AUTOSAR XML (schema 4-3-0)
package /CAN1/ISignalGroup
  26 x i signal group:
    CAN1_SG_ASC2_A: i-signal=[CAN1_AutoTracH, CAN1_DamStiffReqFA, CAN1_DamStiffReqLA, CAN1_DamStiffReqRA, CAN1_KneeCtrlMReq, CAN1_KneeReqFA, CAN1_KneeReqLSide, CAN1_KneeReqRA, CAN1_KneeReqRSide, CAN1_LA1PosCmd, CAN1_LA2PosCmd, CAN1_LvCtrlModeReq, CAN1_NLvReqFA, CAN1_NLvReqRA], system-signal-group=CAN1_SG_ASC2_A
    CAN1_SG_CCVS: i-signal=[CAN1_BrakeSW, CAN1_ParkBrakeSW, CAN1_VCUVehSpd], system-signal-group=CAN1_SG_CCVS
    CAN1_SG_CFGEM1_BAM: i-signal=[CAN1_CFGEM1BAMPGN, CAN1_CFGEM1BAMRsv, CAN1_CFGEM1BAMTNum, CAN1_CFGEM1BAMTSize, CAN1_CFGEM1Ctrl], system-signal-group=CAN1_SG_CFGEM1_BAM
    CAN1_SG_CFGEM1_DT: i-signal=[CAN1_CFGEM1DT0, CAN1_CFGEM1DT1, CAN1_CFGEM1DT2, CAN1_CFGEM1DT3, CAN1_CFGEM1DT4, CAN1_CFGEM1DT5, CAN1_CFGEM1DT6, CAN1_CFGEM1DT7], system-signal-group=CAN1_SG_CFGEM1_DT
    CAN1_SG_DCDC_Status_1: i-signal=[CAN1_DCDCEnSta, CAN1_DCDCErrCode, CAN1_DCDCErrLv, CAN1_DCDCInCurr, CAN1_DCDCInVol, CAN1_DCDCLifeSig, CAN1_DCDCTempe], system-signal-group=CAN1_SG_DCDC_Status_1
    CAN1_SG_DCDC_Status_2: i-signal=[CAN1_DCDCOutCurr, CAN1_DCDCOutVol, CAN1_DCDCSWVer], system-signal-group=CAN1_SG_DCDC_Status_2
    CAN1_SG_EAC_Status_1: i-signal=[CAN1_EACEnSta, CAN1_EACErrCode, CAN1_EACErrLv, CAN1_EACHVILSig, CAN1_EACInVol, CAN1_EACInvTempe, CAN1_EACLifeSig, CAN1_EACMotorTempe], system-signal-group=CAN1_SG_EAC_Status_1
    CAN1_SG_EBC1: i-signal=[CAN1_ABSFullyOper, CAN1_ABSOffroadSw, CAN1_ASRBrakeCtrlAtc, CAN1_ASREngCtrlAtc, CAN1_ASRHillHolderSw, CAN1_ASROffroadSw, CAN1_ATCASRInfoSig, CAN1_AcltrInterlockSw, CAN1_AntiLBrakABSAct, CAN1_BrakePedalPos, CAN1_EBSAmWarnLampSta, CAN1_EBSBrakeSw, CAN1_EBSRedWarnLampSta, CAN1_EngAuxShutdownSw, CAN1_EngDerateSw, CAN1_EngRetSel, CAN1_HaltBrakeSw, CAN1_RmAccelEnSw, CAN1_SACtrlBrakeCtrl, CAN1_TractCtrlOvrSw, CAN1_TrailerABSSta, CAN1_TrailerABSWarnSig], system-signal-group=CAN1_SG_EBC1
    CAN1_SG_EBC2: i-signal=[CAN1_FASpeed, CAN1_RelaSpdFALWheel, CAN1_RelaSpdFARWheel, CAN1_RelaSpdRA1LWheel, CAN1_RelaSpdRA1RWheel, CAN1_RelaSpdRA2LWheel, CAN1_RelaSpdRA2RWheel], system-signal-group=CAN1_SG_EBC2
    CAN1_SG_EBC5: i-signal=[CAN1_BrkTempeWarn, CAN1_FndBrkUse, CAN1_HaltBrkMode, CAN1_HillHolderMode, CAN1_ParkBrkActuFAct, CAN1_XBRAcltnLimit, CAN1_XBRActtrlMode, CAN1_XBRSysSta], system-signal-group=CAN1_SG_EBC5
    CAN1_SG_EEC2: i-signal=[CAN1_AccPedal1LowSW, CAN1_AccPedalPos1, CAN1_EEC2MSGCS, CAN1_EEC2MSGCnt], system-signal-group=CAN1_SG_EEC2
    CAN1_SG_EEC3: i-signal=[CAN1_EMParasLoss, CAN1_NFricPercTorq], system-signal-group=CAN1_SG_EEC3
    CAN1_SG_EHPS_Status_1: i-signal=[CAN1_EHPSEnSta, CAN1_EHPSErrCode, CAN1_EHPSErrLv, CAN1_EHPSHVILSig, CAN1_EHPSInVol, CAN1_EHPSInvTemp, CAN1_EHPSLifeSig, CAN1_EHPSMotorTempe], system-signal-group=CAN1_SG_EHPS_Status_1
    CAN1_SG_EMC1_EM1: i-signal=[CAN1_EM1CS, CAN1_EM1Cnt, CAN1_EM1OvrCtrlMBrk, CAN1_EM1OvrCtrlMDriv, CAN1_EM1OvrCtrlMPriBrk, CAN1_EM1OvrCtrlMPriDriv, CAN1_EM1ReqTorqHRlsBrk, CAN1_EM1ReqTorqHRlsDri, CAN1_EM1ReqTorqLimBrk, CAN1_EM1ReqTorqLimDriv], system-signal-group=CAN1_SG_EMC1_EM1
    CAN1_SG_EMRC1: i-signal=[CAN1_ActEMOutSftSpd, CAN1_ActEMpTrq, CAN1_ActEMpTrqHrls, CAN1_ActMaxAvaEMRecpTrq, CAN1_DrvDemEMRtapTrq, CAN1_EMTrqModeDrvBrk, CAN1_RetSelNonEng, CAN1_SACtrlDev], system-signal-group=CAN1_SG_EMRC1
    CAN1_SG_EPB1: i-signal=CAN1_EPB_ParkingBrake_Sta, system-signal-group=CAN1_SG_EPB1
    CAN1_SG_ETC1: i-signal=[CAN1_DLEngaged, CAN1_ShiftPgs], system-signal-group=CAN1_SG_ETC1
    CAN1_SG_ETC2: i-signal=CAN1_ActDriveDirect, system-signal-group=CAN1_SG_ETC2
    CAN1_SG_FD1_C100_1: i-signal=[CAN1_FDC_CHA_EBSHBSw_Sta, CAN1_FDC_CHA_EBSHHSw_Sta], system-signal-group=CAN1_SG_FD1_C100_1
    CAN1_SG_FD1_C100_2: i-signal=CAN1_FDC_CHA_EBSRd4BR_Sta, system-signal-group=CAN1_SG_FD1_C100_2
    CAN1_SG_FD1_C100_3: i-signal=[CAN1_DCDCEnDemand, CAN1_EACSpdDemand, CAN1_EHPSEnDemand, CAN1_EHPSSpdDemand, CAN1_FDC_CHA_EACEnDemand_Cmd], system-signal-group=CAN1_SG_FD1_C100_3
    CAN1_SG_FD1_CE100_1: i-signal=CAN1_FDC_BCM_DoorSta_Sta, system-signal-group=CAN1_SG_FD1_CE100_1
    CAN1_SG_GW1_C1000_1: i-signal=CAN1_SeatBeltSwitch, system-signal-group=CAN1_SG_GW1_C1000_1
    CAN1_SG_GW1_C100_4: i-signal=[CAN1_OpenStatusOfDoor1, CAN1_OpenStatusOfDoor2], system-signal-group=CAN1_SG_GW1_C100_4
    CAN1_SG_PDU_Status_1: i-signal=[CAN1_HVILSta_T1_PDU, CAN1_PDUACLoopSta, CAN1_PDUACPreRlySta, CAN1_PDUACRlySta, CAN1_PDUDCDCRlySta, CAN1_PDUEACRlySta, CAN1_PDUEHPSRlySta, CAN1_PDULifeSig, CAN1_PDUMCUHVLoopSta, CAN1_PDUMCUPosRlySta, CAN1_PDUMCUPreRlySta, CAN1_PDUSWVer, CAN1_PDUSelfChkSta], system-signal-group=CAN1_SG_PDU_Status_1
    CAN1_SG_VCU_PDU_Demand_1: i-signal=[CAN1_DCDCRlyEn, CAN1_EACRlyEn, CAN1_EHPSRlyEn, CAN1_VCULife1], system-signal-group=CAN1_SG_VCU_PDU_Demand_1
package /CAN1/Cluster
  can cluster CAN1: baudrate=500
    can physical channel CAN1: comm-connectors=ConnCAN1
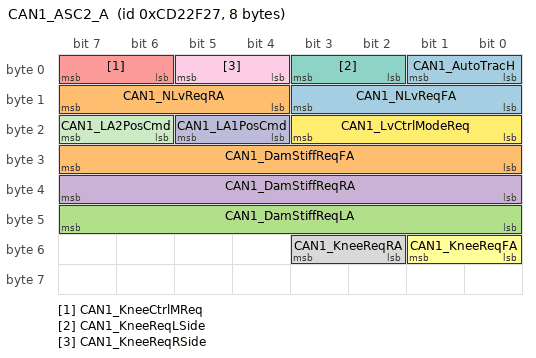
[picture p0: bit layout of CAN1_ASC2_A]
      frame CAN1_ASC2_A: id 0xCD22F27, frame-length=8, can-addressing-mode=EXTENDED, can-fd-frame-support=false, can-frame-rx-behavior=CAN-20, can-frame-tx-behavior=CAN-20
        pdu CAN1_ASC2_A: length=8, minimum-delay=0.0, transmission-mode-true-timing=cyclic-timing=time-period=0.1, unused-bit-pattern=0
          mapping CAN1_SG_ASC2_A: i-signal-group=CAN1_SG_ASC2_A, start-position=0, transfer-property=PENDING
          signal CAN1_AutoTracH: start 0, 2 bit, little-endian, i-signal-type=PRIMITIVE, init-value=constant-reference=Init_CAN1_AutoTracH, base-type=uint8, implementation-data-type=uint8, transfer-property=PENDING
          signal CAN1_DamStiffReqFA: start 24, 8 bit, little-endian, i-signal-type=PRIMITIVE, init-value=constant-reference=Init_CAN1_DamStiffReqFA, base-type=uint8, implementation-data-type=uint8, transfer-property=PENDING
          signal CAN1_DamStiffReqLA: start 40, 8 bit, little-endian, i-signal-type=PRIMITIVE, init-value=constant-reference=Init_CAN1_DamStiffReqLA, base-type=uint8, implementation-data-type=uint8, transfer-property=PENDING
          signal CAN1_DamStiffReqRA: start 32, 8 bit, little-endian, i-signal-type=PRIMITIVE, init-value=constant-reference=Init_CAN1_DamStiffReqRA, base-type=uint8, implementation-data-type=uint8, transfer-property=PENDING
          signal CAN1_KneeCtrlMReq: start 6, 2 bit, little-endian, i-signal-type=PRIMITIVE, init-value=constant-reference=Init_CAN1_KneeCtrlMReq, base-type=uint8, implementation-data-type=uint8, transfer-property=PENDING
          signal CAN1_KneeReqFA: start 48, 2 bit, little-endian, i-signal-type=PRIMITIVE, init-value=constant-reference=Init_CAN1_KneeReqFA, base-type=uint8, implementation-data-type=uint8, transfer-property=PENDING
          signal CAN1_KneeReqLSide: start 2, 2 bit, little-endian, i-signal-type=PRIMITIVE, init-value=constant-reference=Init_CAN1_KneeReqLSide, base-type=uint8, implementation-data-type=uint8, transfer-property=PENDING
          signal CAN1_KneeReqRA: start 50, 2 bit, little-endian, i-signal-type=PRIMITIVE, init-value=constant-reference=Init_CAN1_KneeReqRA, base-type=uint8, implementation-data-type=uint8, transfer-property=PENDING
          signal CAN1_KneeReqRSide: start 4, 2 bit, little-endian, i-signal-type=PRIMITIVE, init-value=constant-reference=Init_CAN1_KneeReqRSide, base-type=uint8, implementation-data-type=uint8, transfer-property=PENDING
          signal CAN1_LA1PosCmd: start 20, 2 bit, little-endian, i-signal-type=PRIMITIVE, init-value=constant-reference=Init_CAN1_LA1PosCmd, base-type=uint8, implementation-data-type=uint8, transfer-property=PENDING
          signal CAN1_LA2PosCmd: start 22, 2 bit, little-endian, i-signal-type=PRIMITIVE, init-value=constant-reference=Init_CAN1_LA2PosCmd, base-type=uint8, implementation-data-type=uint8, transfer-property=PENDING
          signal CAN1_LvCtrlModeReq: start 16, 4 bit, little-endian, i-signal-type=PRIMITIVE, init-value=constant-reference=Init_CAN1_LvCtrlModeReq, base-type=uint8, implementation-data-type=uint8, transfer-property=PENDING
          signal CAN1_NLvReqFA: start 8, 4 bit, little-endian, i-signal-type=PRIMITIVE, init-value=constant-reference=Init_CAN1_NLvReqFA, base-type=uint8, implementation-data-type=uint8, transfer-property=PENDING
          signal CAN1_NLvReqRA: start 12, 4 bit, little-endian, i-signal-type=PRIMITIVE, init-value=constant-reference=Init_CAN1_NLvReqRA, base-type=uint8, implementation-data-type=uint8, transfer-property=PENDING
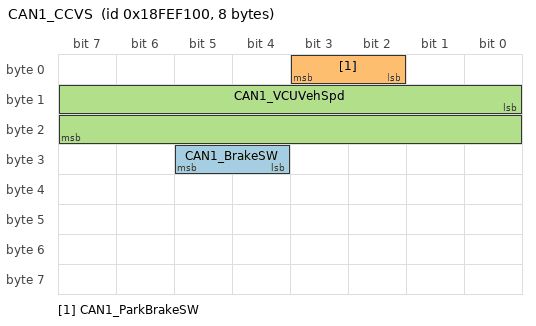
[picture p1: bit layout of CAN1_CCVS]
      frame CAN1_CCVS: id 0x18FEF100, frame-length=8, can-addressing-mode=EXTENDED, can-fd-frame-support=false, can-frame-rx-behavior=CAN-20, can-frame-tx-behavior=CAN-20
        pdu CAN1_CCVS: length=8, minimum-delay=0.0, transmission-mode-true-timing=cyclic-timing=time-period=0.1, unused-bit-pattern=0
          mapping CAN1_SG_CCVS: i-signal-group=CAN1_SG_CCVS, start-position=0, transfer-property=PENDING
          signal CAN1_BrakeSW: start 28, 2 bit, little-endian, i-signal-type=PRIMITIVE, init-value=constant-reference=Init_CAN1_BrakeSW, base-type=uint8, implementation-data-type=uint8, transfer-property=PENDING
          signal CAN1_ParkBrakeSW: start 2, 2 bit, little-endian, i-signal-type=PRIMITIVE, init-value=constant-reference=Init_CAN1_ParkBrakeSW, base-type=uint8, implementation-data-type=uint8, transfer-property=PENDING
          signal CAN1_VCUVehSpd: start 8, 16 bit, little-endian, i-signal-type=PRIMITIVE, init-value=constant-reference=Init_CAN1_VCUVehSpd, base-type=uint16, implementation-data-type=uint16, transfer-property=PENDING
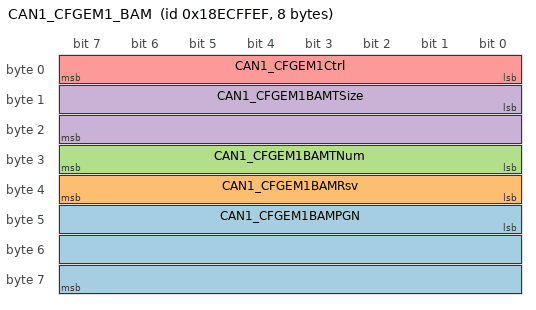
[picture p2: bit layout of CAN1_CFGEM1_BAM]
      frame CAN1_CFGEM1_BAM: id 0x18ECFFEF, frame-length=8, can-addressing-mode=EXTENDED, can-fd-frame-support=false, can-frame-rx-behavior=CAN-20, can-frame-tx-behavior=CAN-20
        pdu CAN1_CFGEM1_BAM: length=8, minimum-delay=0.0, transmission-mode-true-timing=event-controlled-timing={number-of-repetitions=0, repetition-period=0}, unused-bit-pattern=0
          mapping CAN1_SG_CFGEM1_BAM: i-signal-group=CAN1_SG_CFGEM1_BAM, start-position=0, transfer-property=TRIGGERED
          signal CAN1_CFGEM1BAMPGN: start 40, 24 bit, little-endian, i-signal-type=PRIMITIVE, init-value=constant-reference=Init_CAN1_CFGEM1BAMPGN, base-type=uint32, implementation-data-type=uint32, transfer-property=TRIGGERED
          signal CAN1_CFGEM1BAMRsv: start 32, 8 bit, little-endian, i-signal-type=PRIMITIVE, init-value=constant-reference=Init_CAN1_CFGEM1BAMRsv, base-type=uint8, implementation-data-type=uint8, transfer-property=TRIGGERED
          signal CAN1_CFGEM1BAMTNum: start 24, 8 bit, little-endian, i-signal-type=PRIMITIVE, init-value=constant-reference=Init_CAN1_CFGEM1BAMTNum, base-type=uint8, implementation-data-type=uint8, transfer-property=TRIGGERED
          signal CAN1_CFGEM1BAMTSize: start 8, 16 bit, little-endian, i-signal-type=PRIMITIVE, init-value=constant-reference=Init_CAN1_CFGEM1BAMTSize, base-type=uint16, implementation-data-type=uint16, transfer-property=TRIGGERED
          signal CAN1_CFGEM1Ctrl: start 0, 8 bit, little-endian, i-signal-type=PRIMITIVE, init-value=constant-reference=Init_CAN1_CFGEM1Ctrl, base-type=uint8, implementation-data-type=uint8, transfer-property=TRIGGERED
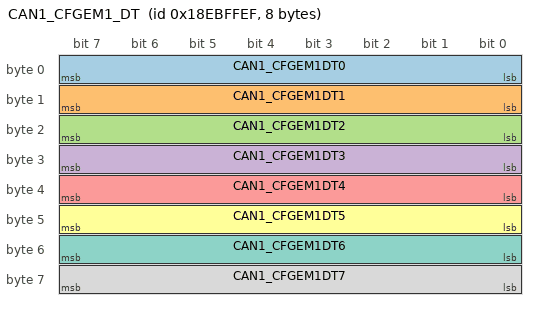
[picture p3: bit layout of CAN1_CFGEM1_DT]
      frame CAN1_CFGEM1_DT: id 0x18EBFFEF, frame-length=8, can-addressing-mode=EXTENDED, can-fd-frame-support=false, can-frame-rx-behavior=CAN-20, can-frame-tx-behavior=CAN-20
        pdu CAN1_CFGEM1_DT: length=8, minimum-delay=0.0, transmission-mode-true-timing=event-controlled-timing={number-of-repetitions=0, repetition-period=0}, unused-bit-pattern=0
          mapping CAN1_SG_CFGEM1_DT: i-signal-group=CAN1_SG_CFGEM1_DT, start-position=0, transfer-property=TRIGGERED
          signal CAN1_CFGEM1DT0: start 0, 8 bit, little-endian, i-signal-type=PRIMITIVE, init-value=constant-reference=Init_CAN1_CFGEM1DT0, base-type=uint8, implementation-data-type=uint8, transfer-property=TRIGGERED
          signal CAN1_CFGEM1DT1: start 8, 8 bit, little-endian, i-signal-type=PRIMITIVE, init-value=constant-reference=Init_CAN1_CFGEM1DT1, base-type=uint8, implementation-data-type=uint8, transfer-property=TRIGGERED
          signal CAN1_CFGEM1DT2: start 16, 8 bit, little-endian, i-signal-type=PRIMITIVE, init-value=constant-reference=Init_CAN1_CFGEM1DT2, base-type=uint8, implementation-data-type=uint8, transfer-property=TRIGGERED
          signal CAN1_CFGEM1DT3: start 24, 8 bit, little-endian, i-signal-type=PRIMITIVE, init-value=constant-reference=Init_CAN1_CFGEM1DT3, base-type=uint8, implementation-data-type=uint8, transfer-property=TRIGGERED
          signal CAN1_CFGEM1DT4: start 32, 8 bit, little-endian, i-signal-type=PRIMITIVE, init-value=constant-reference=Init_CAN1_CFGEM1DT4, base-type=uint8, implementation-data-type=uint8, transfer-property=TRIGGERED
          signal CAN1_CFGEM1DT5: start 40, 8 bit, little-endian, i-signal-type=PRIMITIVE, init-value=constant-reference=Init_CAN1_CFGEM1DT5, base-type=uint8, implementation-data-type=uint8, transfer-property=TRIGGERED
          signal CAN1_CFGEM1DT6: start 48, 8 bit, little-endian, i-signal-type=PRIMITIVE, init-value=constant-reference=Init_CAN1_CFGEM1DT6, base-type=uint8, implementation-data-type=uint8, transfer-property=TRIGGERED
          signal CAN1_CFGEM1DT7: start 56, 8 bit, little-endian, i-signal-type=PRIMITIVE, init-value=constant-reference=Init_CAN1_CFGEM1DT7, base-type=uint8, implementation-data-type=uint8, transfer-property=TRIGGERED
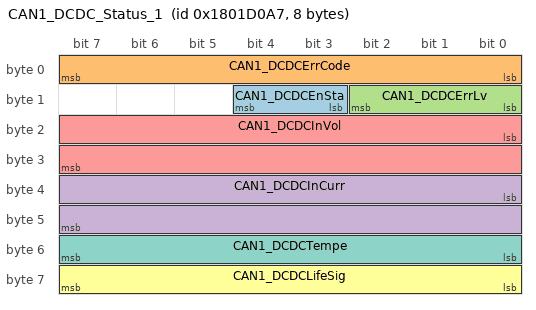
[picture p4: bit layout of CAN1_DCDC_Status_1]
      frame CAN1_DCDC_Status_1: id 0x1801D0A7, frame-length=8, can-addressing-mode=EXTENDED, can-fd-frame-support=false, can-frame-rx-behavior=CAN-20, can-frame-tx-behavior=CAN-20
        pdu CAN1_DCDC_Status_1: length=8, minimum-delay=0.0, transmission-mode-true-timing=cyclic-timing=time-period=0.1, unused-bit-pattern=0
          mapping CAN1_SG_DCDC_Status_1: i-signal-group=CAN1_SG_DCDC_Status_1, start-position=0, transfer-property=PENDING
          signal CAN1_DCDCEnSta: start 11, 2 bit, little-endian, i-signal-type=PRIMITIVE, init-value=constant-reference=Init_CAN1_DCDCEnSta, base-type=uint8, implementation-data-type=uint8, transfer-property=PENDING
          signal CAN1_DCDCErrCode: start 0, 8 bit, little-endian, i-signal-type=PRIMITIVE, init-value=constant-reference=Init_CAN1_DCDCErrCode, base-type=uint8, implementation-data-type=uint8, transfer-property=PENDING
          signal CAN1_DCDCErrLv: start 8, 3 bit, little-endian, i-signal-type=PRIMITIVE, init-value=constant-reference=Init_CAN1_DCDCErrLv, base-type=uint8, implementation-data-type=uint8, transfer-property=PENDING
          signal CAN1_DCDCInCurr: start 32, 16 bit, little-endian, i-signal-type=PRIMITIVE, init-value=constant-reference=Init_CAN1_DCDCInCurr, base-type=uint16, implementation-data-type=uint16, transfer-property=PENDING
          signal CAN1_DCDCInVol: start 16, 16 bit, little-endian, i-signal-type=PRIMITIVE, init-value=constant-reference=Init_CAN1_DCDCInVol, base-type=uint16, implementation-data-type=uint16, transfer-property=PENDING
          signal CAN1_DCDCLifeSig: start 56, 8 bit, little-endian, i-signal-type=PRIMITIVE, init-value=constant-reference=Init_CAN1_DCDCLifeSig, base-type=uint8, implementation-data-type=uint8, transfer-property=PENDING
          signal CAN1_DCDCTempe: start 48, 8 bit, little-endian, i-signal-type=PRIMITIVE, init-value=constant-reference=Init_CAN1_DCDCTempe, base-type=uint8, implementation-data-type=uint8, transfer-property=PENDING
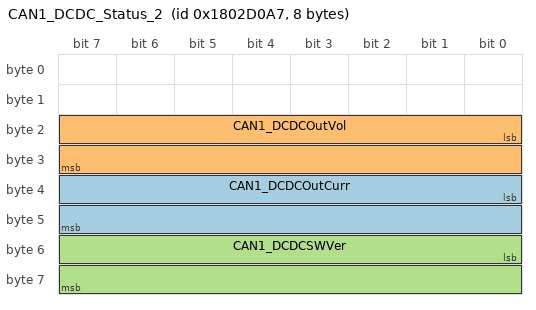
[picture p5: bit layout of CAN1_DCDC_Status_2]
      frame CAN1_DCDC_Status_2: id 0x1802D0A7, frame-length=8, can-addressing-mode=EXTENDED, can-fd-frame-support=false, can-frame-rx-behavior=CAN-20, can-frame-tx-behavior=CAN-20
        pdu CAN1_DCDC_Status_2: length=8, minimum-delay=0.0, transmission-mode-true-timing=cyclic-timing=time-period=1, unused-bit-pattern=0
          mapping CAN1_SG_DCDC_Status_2: i-signal-group=CAN1_SG_DCDC_Status_2, start-position=0, transfer-property=PENDING
          signal CAN1_DCDCOutCurr: start 32, 16 bit, little-endian, i-signal-type=PRIMITIVE, init-value=constant-reference=Init_CAN1_DCDCOutCurr, base-type=uint16, implementation-data-type=uint16, transfer-property=PENDING
          signal CAN1_DCDCOutVol: start 16, 16 bit, little-endian, i-signal-type=PRIMITIVE, init-value=constant-reference=Init_CAN1_DCDCOutVol, base-type=uint16, implementation-data-type=uint16, transfer-property=PENDING
          signal CAN1_DCDCSWVer: start 48, 16 bit, little-endian, i-signal-type=PRIMITIVE, init-value=constant-reference=Init_CAN1_DCDCSWVer, base-type=uint16, implementation-data-type=uint16, transfer-property=PENDING
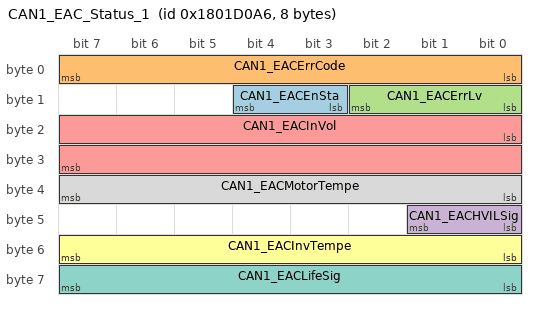
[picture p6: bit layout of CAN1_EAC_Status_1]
      frame CAN1_EAC_Status_1: id 0x1801D0A6, frame-length=8, can-addressing-mode=EXTENDED, can-fd-frame-support=false, can-frame-rx-behavior=CAN-20, can-frame-tx-behavior=CAN-20
        pdu CAN1_EAC_Status_1: length=8, minimum-delay=0.0, transmission-mode-true-timing=cyclic-timing=time-period=0.1, unused-bit-pattern=0
          mapping CAN1_SG_EAC_Status_1: i-signal-group=CAN1_SG_EAC_Status_1, start-position=0, transfer-property=PENDING
          signal CAN1_EACEnSta: start 11, 2 bit, little-endian, i-signal-type=PRIMITIVE, init-value=constant-reference=Init_CAN1_EACEnSta, base-type=uint8, implementation-data-type=uint8, transfer-property=PENDING
          signal CAN1_EACErrCode: start 0, 8 bit, little-endian, i-signal-type=PRIMITIVE, init-value=constant-reference=Init_CAN1_EACErrCode, base-type=uint8, implementation-data-type=uint8, transfer-property=PENDING
          signal CAN1_EACErrLv: start 8, 3 bit, little-endian, i-signal-type=PRIMITIVE, init-value=constant-reference=Init_CAN1_EACErrLv, base-type=uint8, implementation-data-type=uint8, transfer-property=PENDING
          signal CAN1_EACHVILSig: start 40, 2 bit, little-endian, i-signal-type=PRIMITIVE, init-value=constant-reference=Init_CAN1_EACHVILSig, base-type=uint8, implementation-data-type=uint8, transfer-property=PENDING
          signal CAN1_EACInVol: start 16, 16 bit, little-endian, i-signal-type=PRIMITIVE, init-value=constant-reference=Init_CAN1_EACInVol, base-type=uint16, implementation-data-type=uint16, transfer-property=PENDING
          signal CAN1_EACInvTempe: start 48, 8 bit, little-endian, i-signal-type=PRIMITIVE, init-value=constant-reference=Init_CAN1_EACInvTempe, base-type=uint8, implementation-data-type=uint8, transfer-property=PENDING
          signal CAN1_EACLifeSig: start 56, 8 bit, little-endian, i-signal-type=PRIMITIVE, init-value=constant-reference=Init_CAN1_EACLifeSig, base-type=uint8, implementation-data-type=uint8, transfer-property=PENDING
          signal CAN1_EACMotorTempe: start 32, 8 bit, little-endian, i-signal-type=PRIMITIVE, init-value=constant-reference=Init_CAN1_EACMotorTempe, base-type=uint8, implementation-data-type=uint8, transfer-property=PENDING
      frame CAN1_EBC1: id 0x18F0010B, frame-length=8, can-addressing-mode=EXTENDED, can-fd-frame-support=false, can-frame-rx-behavior=CAN-20, can-frame-tx-behavior=CAN-20
        pdu CAN1_EBC1: length=8, minimum-delay=0.0, transmission-mode-true-timing=cyclic-timing=time-period=0.1, unused-bit-pattern=0
          mapping CAN1_SG_EBC1: i-signal-group=CAN1_SG_EBC1, start-position=0, transfer-property=PENDING
          signal CAN1_ABSFullyOper: start 40, 2 bit, little-endian, i-signal-type=PRIMITIVE, init-value=constant-reference=Init_CAN1_ABSFullyOper, base-type=uint8, implementation-data-type=uint8, transfer-property=PENDING
          signal CAN1_ABSOffroadSw: start 16, 2 bit, little-endian, i-signal-type=PRIMITIVE, init-value=constant-reference=Init_CAN1_ABSOffroadSw, base-type=uint8, implementation-data-type=uint8, transfer-property=PENDING
          signal CAN1_ASRBrakeCtrlAtc: start 2, 2 bit, little-endian, i-signal-type=PRIMITIVE, init-value=constant-reference=Init_CAN1_ASRBrakeCtrlAtc, base-type=uint8, implementation-data-type=uint8, transfer-property=PENDING
          signal CAN1_ASREngCtrlAtc: start 0, 2 bit, little-endian, i-signal-type=PRIMITIVE, init-value=constant-reference=Init_CAN1_ASREngCtrlAtc, base-type=uint8, implementation-data-type=uint8, transfer-property=PENDING
          signal CAN1_ASRHillHolderSw: start 20, 2 bit, little-endian, i-signal-type=PRIMITIVE, init-value=constant-reference=Init_CAN1_ASRHillHolderSw, base-type=uint8, implementation-data-type=uint8, transfer-property=PENDING
          signal CAN1_ASROffroadSw: start 18, 2 bit, little-endian, i-signal-type=PRIMITIVE, init-value=constant-reference=Init_CAN1_ASROffroadSw, base-type=uint8, implementation-data-type=uint8, transfer-property=PENDING
          signal CAN1_ATCASRInfoSig: start 46, 2 bit, little-endian, i-signal-type=PRIMITIVE, init-value=constant-reference=Init_CAN1_ATCASRInfoSig, base-type=uint8, implementation-data-type=uint8, transfer-property=PENDING
          signal CAN1_AcltrInterlockSw: start 24, 2 bit, little-endian, i-signal-type=PRIMITIVE, init-value=constant-reference=Init_CAN1_AcltrInterlockSw, base-type=uint8, implementation-data-type=uint8, transfer-property=PENDING
          signal CAN1_AntiLBrakABSAct: start 4, 2 bit, little-endian, i-signal-type=PRIMITIVE, init-value=constant-reference=Init_CAN1_AntiLBrakABSAct, base-type=uint8, implementation-data-type=uint8, transfer-property=PENDING
          signal CAN1_BrakePedalPos: start 8, 8 bit, little-endian, i-signal-type=PRIMITIVE, init-value=constant-reference=Init_CAN1_BrakePedalPos, base-type=uint8, implementation-data-type=uint8, transfer-property=PENDING
          signal CAN1_EBSAmWarnLampSta: start 44, 2 bit, little-endian, i-signal-type=PRIMITIVE, init-value=constant-reference=Init_CAN1_EBSAmWarnLampSta, base-type=uint8, implementation-data-type=uint8, transfer-property=PENDING
          signal CAN1_EBSBrakeSw: start 6, 2 bit, little-endian, i-signal-type=PRIMITIVE, init-value=constant-reference=Init_CAN1_EBSBrakeSw, base-type=uint8, implementation-data-type=uint8, transfer-property=PENDING
          signal CAN1_EBSRedWarnLampSta: start 42, 2 bit, little-endian, i-signal-type=PRIMITIVE, init-value=constant-reference=Init_CAN1_EBSRedWarnLampSta, base-type=uint8, implementation-data-type=uint8, transfer-property=PENDING
          signal CAN1_EngAuxShutdownSw: start 28, 2 bit, little-endian, i-signal-type=PRIMITIVE, init-value=constant-reference=Init_CAN1_EngAuxShutdownSw, base-type=uint8, implementation-data-type=uint8, transfer-property=PENDING
          signal CAN1_EngDerateSw: start 26, 2 bit, little-endian, i-signal-type=PRIMITIVE, init-value=constant-reference=Init_CAN1_EngDerateSw, base-type=uint8, implementation-data-type=uint8, transfer-property=PENDING
          signal CAN1_EngRetSel: start 32, 8 bit, little-endian, i-signal-type=PRIMITIVE, init-value=constant-reference=Init_CAN1_EngRetSel, base-type=uint8, implementation-data-type=uint8, transfer-property=PENDING
          signal CAN1_HaltBrakeSw: start 58, 2 bit, little-endian, i-signal-type=PRIMITIVE, init-value=constant-reference=Init_CAN1_HaltBrakeSw, base-type=uint8, implementation-data-type=uint8, transfer-property=PENDING
          signal CAN1_RmAccelEnSw: start 30, 2 bit, little-endian, i-signal-type=PRIMITIVE, init-value=constant-reference=Init_CAN1_RmAccelEnSw, base-type=uint8, implementation-data-type=uint8, transfer-property=PENDING
          signal CAN1_SACtrlBrakeCtrl: start 48, 8 bit, little-endian, i-signal-type=PRIMITIVE, init-value=constant-reference=Init_CAN1_SACtrlBrakeCtrl, base-type=uint8, implementation-data-type=uint8, transfer-property=PENDING
          signal CAN1_TractCtrlOvrSw: start 22, 2 bit, little-endian, i-signal-type=PRIMITIVE, init-value=constant-reference=Init_CAN1_TractCtrlOvrSw, base-type=uint8, implementation-data-type=uint8, transfer-property=PENDING
          signal CAN1_TrailerABSSta: start 60, 2 bit, little-endian, i-signal-type=PRIMITIVE, init-value=constant-reference=Init_CAN1_TrailerABSSta, base-type=uint8, implementation-data-type=uint8, transfer-property=PENDING
          signal CAN1_TrailerABSWarnSig: start 62, 2 bit, little-endian, i-signal-type=PRIMITIVE, init-value=constant-reference=Init_CAN1_TrailerABSWarnSig, base-type=uint8, implementation-data-type=uint8, transfer-property=PENDING
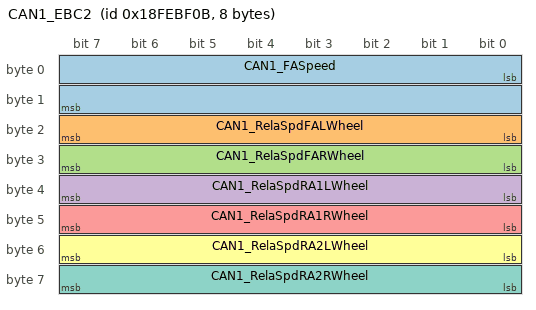
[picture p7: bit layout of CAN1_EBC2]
      frame CAN1_EBC2: id 0x18FEBF0B, frame-length=8, can-addressing-mode=EXTENDED, can-fd-frame-support=false, can-frame-rx-behavior=CAN-20, can-frame-tx-behavior=CAN-20
        pdu CAN1_EBC2: length=8, minimum-delay=0.0, transmission-mode-true-timing=cyclic-timing=time-period=0.1, unused-bit-pattern=0
          mapping CAN1_SG_EBC2: i-signal-group=CAN1_SG_EBC2, start-position=0, transfer-property=PENDING
          signal CAN1_FASpeed: start 0, 16 bit, little-endian, i-signal-type=PRIMITIVE, init-value=constant-reference=Init_CAN1_FASpeed, base-type=uint16, implementation-data-type=uint16, transfer-property=PENDING
          signal CAN1_RelaSpdFALWheel: start 16, 8 bit, little-endian, i-signal-type=PRIMITIVE, init-value=constant-reference=Init_CAN1_RelaSpdFALWheel, base-type=uint8, implementation-data-type=uint8, transfer-property=PENDING
          signal CAN1_RelaSpdFARWheel: start 24, 8 bit, little-endian, i-signal-type=PRIMITIVE, init-value=constant-reference=Init_CAN1_RelaSpdFARWheel, base-type=uint8, implementation-data-type=uint8, transfer-property=PENDING
          signal CAN1_RelaSpdRA1LWheel: start 32, 8 bit, little-endian, i-signal-type=PRIMITIVE, init-value=constant-reference=Init_CAN1_RelaSpdRA1LWheel, base-type=uint8, implementation-data-type=uint8, transfer-property=PENDING
          signal CAN1_RelaSpdRA1RWheel: start 40, 8 bit, little-endian, i-signal-type=PRIMITIVE, init-value=constant-reference=Init_CAN1_RelaSpdRA1RWheel, base-type=uint8, implementation-data-type=uint8, transfer-property=PENDING
          signal CAN1_RelaSpdRA2LWheel: start 48, 8 bit, little-endian, i-signal-type=PRIMITIVE, init-value=constant-reference=Init_CAN1_RelaSpdRA2LWheel, base-type=uint8, implementation-data-type=uint8, transfer-property=PENDING
          signal CAN1_RelaSpdRA2RWheel: start 56, 8 bit, little-endian, i-signal-type=PRIMITIVE, init-value=constant-reference=Init_CAN1_RelaSpdRA2RWheel, base-type=uint8, implementation-data-type=uint8, transfer-property=PENDING
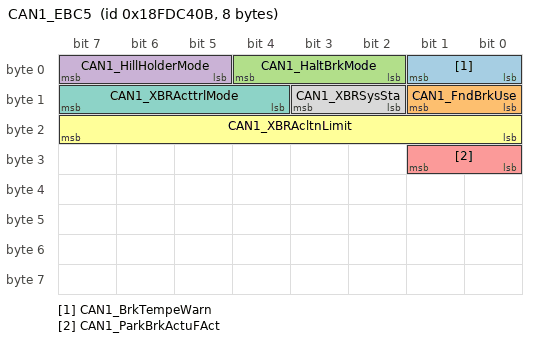
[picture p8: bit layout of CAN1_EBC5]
      frame CAN1_EBC5: id 0x18FDC40B, frame-length=8, can-addressing-mode=EXTENDED, can-fd-frame-support=false, can-frame-rx-behavior=CAN-20, can-frame-tx-behavior=CAN-20
        pdu CAN1_EBC5: length=8, minimum-delay=0.0, transmission-mode-true-timing=cyclic-timing=time-period=0.1, unused-bit-pattern=0
          mapping CAN1_SG_EBC5: i-signal-group=CAN1_SG_EBC5, start-position=0, transfer-property=PENDING
          signal CAN1_BrkTempeWarn: start 0, 2 bit, little-endian, i-signal-type=PRIMITIVE, init-value=constant-reference=Init_CAN1_BrkTempeWarn, base-type=uint8, implementation-data-type=uint8, transfer-property=PENDING
          signal CAN1_FndBrkUse: start 8, 2 bit, little-endian, i-signal-type=PRIMITIVE, init-value=constant-reference=Init_CAN1_FndBrkUse, base-type=uint8, implementation-data-type=uint8, transfer-property=PENDING
          signal CAN1_HaltBrkMode: start 2, 3 bit, little-endian, i-signal-type=PRIMITIVE, init-value=constant-reference=Init_CAN1_HaltBrkMode, base-type=uint8, implementation-data-type=uint8, transfer-property=PENDING
          signal CAN1_HillHolderMode: start 5, 3 bit, little-endian, i-signal-type=PRIMITIVE, init-value=constant-reference=Init_CAN1_HillHolderMode, base-type=uint8, implementation-data-type=uint8, transfer-property=PENDING
          signal CAN1_ParkBrkActuFAct: start 24, 2 bit, little-endian, i-signal-type=PRIMITIVE, init-value=constant-reference=Init_CAN1_ParkBrkActuFAct, base-type=uint8, implementation-data-type=uint8, transfer-property=PENDING
          signal CAN1_XBRAcltnLimit: start 16, 8 bit, little-endian, i-signal-type=PRIMITIVE, init-value=constant-reference=Init_CAN1_XBRAcltnLimit, base-type=uint8, implementation-data-type=uint8, transfer-property=PENDING
          signal CAN1_XBRActtrlMode: start 12, 4 bit, little-endian, i-signal-type=PRIMITIVE, init-value=constant-reference=Init_CAN1_XBRActtrlMode, base-type=uint8, implementation-data-type=uint8, transfer-property=PENDING
          signal CAN1_XBRSysSta: start 10, 2 bit, little-endian, i-signal-type=PRIMITIVE, init-value=constant-reference=Init_CAN1_XBRSysSta, base-type=uint8, implementation-data-type=uint8, transfer-property=PENDING
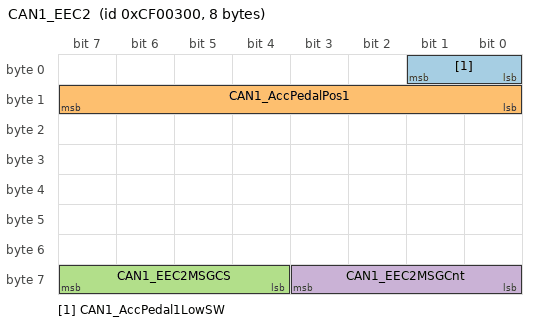
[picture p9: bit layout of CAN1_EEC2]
      frame CAN1_EEC2: id 0xCF00300, frame-length=8, can-addressing-mode=EXTENDED, can-fd-frame-support=false, can-frame-rx-behavior=CAN-20, can-frame-tx-behavior=CAN-20
        pdu CAN1_EEC2: length=8, minimum-delay=0.0, transmission-mode-true-timing=cyclic-timing=time-period=0.05, unused-bit-pattern=0
          mapping CAN1_SG_EEC2: i-signal-group=CAN1_SG_EEC2, start-position=0, transfer-property=PENDING
          signal CAN1_AccPedal1LowSW: start 0, 2 bit, little-endian, i-signal-type=PRIMITIVE, init-value=constant-reference=Init_CAN1_AccPedal1LowSW, base-type=uint8, implementation-data-type=uint8, transfer-property=PENDING
          signal CAN1_AccPedalPos1: start 8, 8 bit, little-endian, i-signal-type=PRIMITIVE, init-value=constant-reference=Init_CAN1_AccPedalPos1, base-type=uint8, implementation-data-type=uint8, transfer-property=PENDING
          signal CAN1_EEC2MSGCS: start 60, 4 bit, little-endian, i-signal-type=PRIMITIVE, init-value=constant-reference=Init_CAN1_EEC2MSGCS, base-type=uint8, implementation-data-type=uint8, transfer-property=PENDING
          signal CAN1_EEC2MSGCnt: start 56, 4 bit, little-endian, i-signal-type=PRIMITIVE, init-value=constant-reference=Init_CAN1_EEC2MSGCnt, base-type=uint8, implementation-data-type=uint8, transfer-property=PENDING
      frame CAN1_EEC3: id 0x18FEDFEF, frame-length=8, can-addressing-mode=EXTENDED, can-fd-frame-support=false, can-frame-rx-behavior=CAN-20, can-frame-tx-behavior=CAN-20
        pdu CAN1_EEC3: length=8, minimum-delay=0.0, transmission-mode-true-timing=cyclic-timing=time-period=0.25, unused-bit-pattern=0
          mapping CAN1_SG_EEC3: i-signal-group=CAN1_SG_EEC3, start-position=0, transfer-property=PENDING
          signal CAN1_EMParasLoss: start 32, 8 bit, little-endian, i-signal-type=PRIMITIVE, init-value=constant-reference=Init_CAN1_EMParasLoss, base-type=uint8, implementation-data-type=uint8, transfer-property=PENDING
          signal CAN1_NFricPercTorq: start 0, 8 bit, little-endian, i-signal-type=PRIMITIVE, init-value=constant-reference=Init_CAN1_NFricPercTorq, base-type=uint8, implementation-data-type=uint8, transfer-property=PENDING
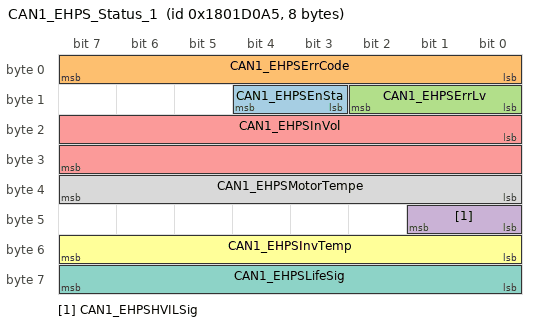
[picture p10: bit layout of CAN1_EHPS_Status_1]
      frame CAN1_EHPS_Status_1: id 0x1801D0A5, frame-length=8, can-addressing-mode=EXTENDED, can-fd-frame-support=false, can-frame-rx-behavior=CAN-20, can-frame-tx-behavior=CAN-20
        pdu CAN1_EHPS_Status_1: length=8, minimum-delay=0.0, transmission-mode-true-timing=cyclic-timing=time-period=0.1, unused-bit-pattern=0
          mapping CAN1_SG_EHPS_Status_1: i-signal-group=CAN1_SG_EHPS_Status_1, start-position=0, transfer-property=PENDING
          signal CAN1_EHPSEnSta: start 11, 2 bit, little-endian, i-signal-type=PRIMITIVE, init-value=constant-reference=Init_CAN1_EHPSEnSta, base-type=uint8, implementation-data-type=uint8, transfer-property=PENDING
          signal CAN1_EHPSErrCode: start 0, 8 bit, little-endian, i-signal-type=PRIMITIVE, init-value=constant-reference=Init_CAN1_EHPSErrCode, base-type=uint8, implementation-data-type=uint8, transfer-property=PENDING
          signal CAN1_EHPSErrLv: start 8, 3 bit, little-endian, i-signal-type=PRIMITIVE, init-value=constant-reference=Init_CAN1_EHPSErrLv, base-type=uint8, implementation-data-type=uint8, transfer-property=PENDING
          signal CAN1_EHPSHVILSig: start 40, 2 bit, little-endian, i-signal-type=PRIMITIVE, init-value=constant-reference=Init_CAN1_EHPSHVILSig, base-type=uint8, implementation-data-type=uint8, transfer-property=PENDING
          signal CAN1_EHPSInVol: start 16, 16 bit, little-endian, i-signal-type=PRIMITIVE, init-value=constant-reference=Init_CAN1_EHPSInVol, base-type=uint16, implementation-data-type=uint16, transfer-property=PENDING
          signal CAN1_EHPSInvTemp: start 48, 8 bit, little-endian, i-signal-type=PRIMITIVE, init-value=constant-reference=Init_CAN1_EHPSInvTemp, base-type=uint8, implementation-data-type=uint8, transfer-property=PENDING
          signal CAN1_EHPSLifeSig: start 56, 8 bit, little-endian, i-signal-type=PRIMITIVE, init-value=constant-reference=Init_CAN1_EHPSLifeSig, base-type=uint8, implementation-data-type=uint8, transfer-property=PENDING
          signal CAN1_EHPSMotorTempe: start 32, 8 bit, little-endian, i-signal-type=PRIMITIVE, init-value=constant-reference=Init_CAN1_EHPSMotorTempe, base-type=uint8, implementation-data-type=uint8, transfer-property=PENDING
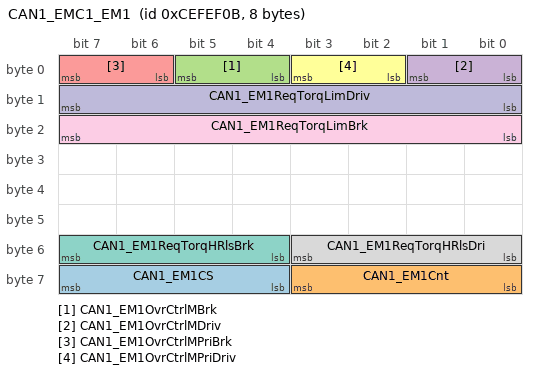
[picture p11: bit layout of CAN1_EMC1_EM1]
      frame CAN1_EMC1_EM1: id 0xCEFEF0B, frame-length=8, can-addressing-mode=EXTENDED, can-fd-frame-support=false, can-frame-rx-behavior=CAN-20, can-frame-tx-behavior=CAN-20
        pdu CAN1_EMC1_EM1: length=8, minimum-delay=0.0, transmission-mode-true-timing=cyclic-timing=time-period=0.1, unused-bit-pattern=0
          mapping CAN1_SG_EMC1_EM1: i-signal-group=CAN1_SG_EMC1_EM1, start-position=0, transfer-property=PENDING
          signal CAN1_EM1CS: start 60, 4 bit, little-endian, i-signal-type=PRIMITIVE, init-value=constant-reference=Init_CAN1_EM1CS, base-type=uint8, implementation-data-type=uint8, transfer-property=PENDING
          signal CAN1_EM1Cnt: start 56, 4 bit, little-endian, i-signal-type=PRIMITIVE, init-value=constant-reference=Init_CAN1_EM1Cnt, base-type=uint8, implementation-data-type=uint8, transfer-property=PENDING
          signal CAN1_EM1OvrCtrlMBrk: start 4, 2 bit, little-endian, i-signal-type=PRIMITIVE, init-value=constant-reference=Init_CAN1_EM1OvrCtrlMBrk, base-type=uint8, implementation-data-type=uint8, transfer-property=PENDING
          signal CAN1_EM1OvrCtrlMDriv: start 0, 2 bit, little-endian, i-signal-type=PRIMITIVE, init-value=constant-reference=Init_CAN1_EM1OvrCtrlMDriv, base-type=uint8, implementation-data-type=uint8, transfer-property=PENDING
          signal CAN1_EM1OvrCtrlMPriBrk: start 6, 2 bit, little-endian, i-signal-type=PRIMITIVE, init-value=constant-reference=Init_CAN1_EM1OvrCtrlMPriBrk, base-type=uint8, implementation-data-type=uint8, transfer-property=PENDING
          signal CAN1_EM1OvrCtrlMPriDriv: start 2, 2 bit, little-endian, i-signal-type=PRIMITIVE, init-value=constant-reference=Init_CAN1_EM1OvrCtrlMPriDriv, base-type=uint8, implementation-data-type=uint8, transfer-property=PENDING
          signal CAN1_EM1ReqTorqHRlsBrk: start 52, 4 bit, little-endian, i-signal-type=PRIMITIVE, init-value=constant-reference=Init_CAN1_EM1ReqTorqHRlsBrk, base-type=uint8, implementation-data-type=uint8, transfer-property=PENDING
          signal CAN1_EM1ReqTorqHRlsDri: start 48, 4 bit, little-endian, i-signal-type=PRIMITIVE, init-value=constant-reference=Init_CAN1_EM1ReqTorqHRlsDri, base-type=uint8, implementation-data-type=uint8, transfer-property=PENDING
          signal CAN1_EM1ReqTorqLimBrk: start 16, 8 bit, little-endian, i-signal-type=PRIMITIVE, init-value=constant-reference=Init_CAN1_EM1ReqTorqLimBrk, base-type=uint8, implementation-data-type=uint8, transfer-property=PENDING
          signal CAN1_EM1ReqTorqLimDriv: start 8, 8 bit, little-endian, i-signal-type=PRIMITIVE, init-value=constant-reference=Init_CAN1_EM1ReqTorqLimDriv, base-type=uint8, implementation-data-type=uint8, transfer-property=PENDING
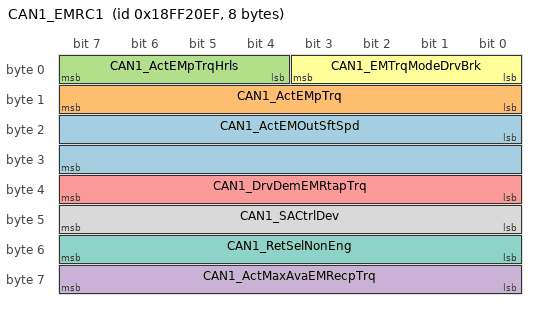
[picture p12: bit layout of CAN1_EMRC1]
      frame CAN1_EMRC1: id 0x18FF20EF, frame-length=8, can-addressing-mode=EXTENDED, can-fd-frame-support=false, can-frame-rx-behavior=CAN-20, can-frame-tx-behavior=CAN-20
        pdu CAN1_EMRC1: length=8, minimum-delay=0.0, transmission-mode-true-timing=cyclic-timing=time-period=0.01, unused-bit-pattern=0
          mapping CAN1_SG_EMRC1: i-signal-group=CAN1_SG_EMRC1, start-position=0, transfer-property=PENDING
          signal CAN1_ActEMOutSftSpd: start 16, 16 bit, little-endian, i-signal-type=PRIMITIVE, init-value=constant-reference=Init_CAN1_ActEMOutSftSpd, base-type=uint16, implementation-data-type=uint16, transfer-property=PENDING
          signal CAN1_ActEMpTrq: start 8, 8 bit, little-endian, i-signal-type=PRIMITIVE, init-value=constant-reference=Init_CAN1_ActEMpTrq, base-type=uint8, implementation-data-type=uint8, transfer-property=PENDING
          signal CAN1_ActEMpTrqHrls: start 4, 4 bit, little-endian, i-signal-type=PRIMITIVE, init-value=constant-reference=Init_CAN1_ActEMpTrqHrls, base-type=uint8, implementation-data-type=uint8, transfer-property=PENDING
          signal CAN1_ActMaxAvaEMRecpTrq: start 56, 8 bit, little-endian, i-signal-type=PRIMITIVE, init-value=constant-reference=Init_CAN1_ActMaxAvaEMRecpTrq, base-type=uint8, implementation-data-type=uint8, transfer-property=PENDING
          signal CAN1_DrvDemEMRtapTrq: start 32, 8 bit, little-endian, i-signal-type=PRIMITIVE, init-value=constant-reference=Init_CAN1_DrvDemEMRtapTrq, base-type=uint8, implementation-data-type=uint8, transfer-property=PENDING
          signal CAN1_EMTrqModeDrvBrk: start 0, 4 bit, little-endian, i-signal-type=PRIMITIVE, init-value=constant-reference=Init_CAN1_EMTrqModeDrvBrk, base-type=uint8, implementation-data-type=uint8, transfer-property=PENDING
          signal CAN1_RetSelNonEng: start 48, 8 bit, little-endian, i-signal-type=PRIMITIVE, init-value=constant-reference=Init_CAN1_RetSelNonEng, base-type=uint8, implementation-data-type=uint8, transfer-property=PENDING
          signal CAN1_SACtrlDev: start 40, 8 bit, little-endian, i-signal-type=PRIMITIVE, init-value=constant-reference=Init_CAN1_SACtrlDev, base-type=uint8, implementation-data-type=uint8, transfer-property=PENDING
      frame CAN1_EPB1: id 0x18FEF150, frame-length=8, can-addressing-mode=EXTENDED, can-fd-frame-support=false, can-frame-rx-behavior=CAN-20, can-frame-tx-behavior=CAN-20
        pdu CAN1_EPB1: length=8, minimum-delay=0.0, transmission-mode-true-timing=cyclic-timing=time-period=0.1, unused-bit-pattern=0
          mapping CAN1_SG_EPB1: i-signal-group=CAN1_SG_EPB1, start-position=0, transfer-property=PENDING
          signal CAN1_EPB_ParkingBrake_Sta: start 2, 2 bit, little-endian, i-signal-type=PRIMITIVE, init-value=constant-reference=Init_CAN1_EPB_ParkingBrake_Sta, base-type=uint8, implementation-data-type=uint8, transfer-property=PENDING
      frame CAN1_ETC1: id 0x18F00203, frame-length=8, can-addressing-mode=EXTENDED, can-fd-frame-support=false, can-frame-rx-behavior=CAN-20, can-frame-tx-behavior=CAN-20
        pdu CAN1_ETC1: length=8, minimum-delay=0.0, transmission-mode-true-timing=cyclic-timing=time-period=0.08, unused-bit-pattern=0
          mapping CAN1_SG_ETC1: i-signal-group=CAN1_SG_ETC1, start-position=0, transfer-property=PENDING
          signal CAN1_DLEngaged: start 0, 2 bit, little-endian, i-signal-type=PRIMITIVE, init-value=constant-reference=Init_CAN1_DLEngaged, base-type=uint8, implementation-data-type=uint8, transfer-property=PENDING
          signal CAN1_ShiftPgs: start 4, 2 bit, little-endian, i-signal-type=PRIMITIVE, init-value=constant-reference=Init_CAN1_ShiftPgs, base-type=uint8, implementation-data-type=uint8, transfer-property=PENDING
      frame CAN1_ETC2: id 0x18F00503, frame-length=8, can-addressing-mode=EXTENDED, can-fd-frame-support=false, can-frame-rx-behavior=CAN-20, can-frame-tx-behavior=CAN-20
        pdu CAN1_ETC2: length=8, minimum-delay=0.0, transmission-mode-true-timing=cyclic-timing=time-period=0.05, unused-bit-pattern=0
          mapping CAN1_SG_ETC2: i-signal-group=CAN1_SG_ETC2, start-position=0, transfer-property=PENDING
          signal CAN1_ActDriveDirect: start 24, 8 bit, little-endian, i-signal-type=PRIMITIVE, init-value=constant-reference=Init_CAN1_ActDriveDirect, base-type=uint8, implementation-data-type=uint8, transfer-property=PENDING
      frame CAN1_FD1_C100_1: id 0x18FF602B, frame-length=8, can-addressing-mode=EXTENDED, can-fd-frame-support=false, can-frame-rx-behavior=CAN-20, can-frame-tx-behavior=CAN-20
        pdu CAN1_FD1_C100_1: length=8, minimum-delay=0.0, transmission-mode-true-timing=cyclic-timing=time-period=0.1, unused-bit-pattern=0
          mapping CAN1_SG_FD1_C100_1: i-signal-group=CAN1_SG_FD1_C100_1, start-position=0, transfer-property=PENDING
          signal CAN1_FDC_CHA_EBSHBSw_Sta: start 6, 2 bit, little-endian, i-signal-type=PRIMITIVE, init-value=constant-reference=Init_CAN1_FDC_CHA_EBSHBSw_Sta, base-type=uint8, implementation-data-type=uint8, transfer-property=PENDING
          signal CAN1_FDC_CHA_EBSHHSw_Sta: start 4, 2 bit, little-endian, i-signal-type=PRIMITIVE, init-value=constant-reference=Init_CAN1_FDC_CHA_EBSHHSw_Sta, base-type=uint8, implementation-data-type=uint8, transfer-property=PENDING
      frame CAN1_FD1_C100_2: id 0x18FE4A03, frame-length=8, can-addressing-mode=EXTENDED, can-fd-frame-support=false, can-frame-rx-behavior=CAN-20, can-frame-tx-behavior=CAN-20
        pdu CAN1_FD1_C100_2: length=8, minimum-delay=0.0, transmission-mode-true-timing=cyclic-timing=time-period=0.1, unused-bit-pattern=0
          mapping CAN1_SG_FD1_C100_2: i-signal-group=CAN1_SG_FD1_C100_2, start-position=0, transfer-property=PENDING
          signal CAN1_FDC_CHA_EBSRd4BR_Sta: start 8, 2 bit, little-endian, i-signal-type=PRIMITIVE, init-value=constant-reference=Init_CAN1_FDC_CHA_EBSRd4BR_Sta, base-type=uint8, implementation-data-type=uint8, transfer-property=PENDING
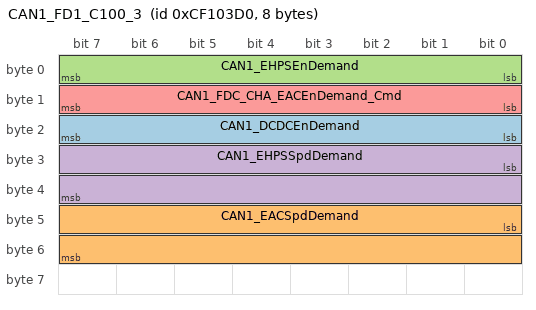
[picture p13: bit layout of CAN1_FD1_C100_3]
      frame CAN1_FD1_C100_3: id 0xCF103D0, frame-length=8, can-addressing-mode=EXTENDED, can-fd-frame-support=false, can-frame-rx-behavior=CAN-20, can-frame-tx-behavior=CAN-20
        pdu CAN1_FD1_C100_3: length=8, minimum-delay=0.0, transmission-mode-true-timing=cyclic-timing=time-period=0.1, unused-bit-pattern=0
          mapping CAN1_SG_FD1_C100_3: i-signal-group=CAN1_SG_FD1_C100_3, start-position=0, transfer-property=PENDING
          signal CAN1_DCDCEnDemand: start 16, 8 bit, little-endian, i-signal-type=PRIMITIVE, init-value=constant-reference=Init_CAN1_DCDCEnDemand, base-type=uint8, implementation-data-type=uint8, transfer-property=PENDING
          signal CAN1_EACSpdDemand: start 40, 16 bit, little-endian, i-signal-type=PRIMITIVE, init-value=constant-reference=Init_CAN1_EACSpdDemand, base-type=uint16, implementation-data-type=uint16, transfer-property=PENDING
          signal CAN1_EHPSEnDemand: start 0, 8 bit, little-endian, i-signal-type=PRIMITIVE, init-value=constant-reference=Init_CAN1_EHPSEnDemand, base-type=uint8, implementation-data-type=uint8, transfer-property=PENDING
          signal CAN1_EHPSSpdDemand: start 24, 16 bit, little-endian, i-signal-type=PRIMITIVE, init-value=constant-reference=Init_CAN1_EHPSSpdDemand, base-type=uint16, implementation-data-type=uint16, transfer-property=PENDING
          signal CAN1_FDC_CHA_EACEnDemand_Cmd: start 8, 8 bit, little-endian, i-signal-type=PRIMITIVE, init-value=constant-reference=Init_CAN1_FDC_CHA_EACEnDemand_Cmd, base-type=uint8, implementation-data-type=uint8, transfer-property=PENDING
      frame CAN1_FD1_CE100_1: id 0x18FE4EEC, frame-length=8, can-addressing-mode=EXTENDED, can-fd-frame-support=false, can-frame-rx-behavior=CAN-20, can-frame-tx-behavior=CAN-20
        pdu CAN1_FD1_CE100_1: length=8, minimum-delay=0.0, transmission-mode-true-timing=cyclic-timing=time-period=0.1, unused-bit-pattern=0
          mapping CAN1_SG_FD1_CE100_1: i-signal-group=CAN1_SG_FD1_CE100_1, start-position=0, transfer-property=PENDING
          signal CAN1_FDC_BCM_DoorSta_Sta: start 0, 4 bit, little-endian, i-signal-type=PRIMITIVE, init-value=constant-reference=Init_CAN1_FDC_BCM_DoorSta_Sta, base-type=uint8, implementation-data-type=uint8, transfer-property=PENDING
      frame CAN1_GW1_C1000_1: id 0x18E0FF21, frame-length=8, can-addressing-mode=EXTENDED, can-fd-frame-support=false, can-frame-rx-behavior=CAN-20, can-frame-tx-behavior=CAN-20
        pdu CAN1_GW1_C1000_1: length=8, minimum-delay=0.0, transmission-mode-true-timing={cyclic-timing=time-period=1, event-controlled-timing={number-of-repetitions=0, repetition-period=0}}, unused-bit-pattern=0
          mapping CAN1_SG_GW1_C1000_1: i-signal-group=CAN1_SG_GW1_C1000_1, start-position=0, transfer-property=TRIGGERED-ON-CHANGE
          signal CAN1_SeatBeltSwitch: start 30, 2 bit, little-endian, i-signal-type=PRIMITIVE, init-value=constant-reference=Init_CAN1_SeatBeltSwitch, base-type=uint8, implementation-data-type=uint8, transfer-property=TRIGGERED-ON-CHANGE
      frame CAN1_GW1_C100_4: id 0x18FDA521, frame-length=8, can-addressing-mode=EXTENDED, can-fd-frame-support=false, can-frame-rx-behavior=CAN-20, can-frame-tx-behavior=CAN-20
        pdu CAN1_GW1_C100_4: length=8, minimum-delay=0.0, transmission-mode-true-timing=cyclic-timing=time-period=0.1, unused-bit-pattern=0
          mapping CAN1_SG_GW1_C100_4: i-signal-group=CAN1_SG_GW1_C100_4, start-position=0, transfer-property=PENDING
          signal CAN1_OpenStatusOfDoor1: start 2, 2 bit, little-endian, i-signal-type=PRIMITIVE, init-value=constant-reference=Init_CAN1_OpenStatusOfDoor1, base-type=uint8, implementation-data-type=uint8, transfer-property=PENDING
          signal CAN1_OpenStatusOfDoor2: start 8, 2 bit, little-endian, i-signal-type=PRIMITIVE, init-value=constant-reference=Init_CAN1_OpenStatusOfDoor2, base-type=uint8, implementation-data-type=uint8, transfer-property=PENDING
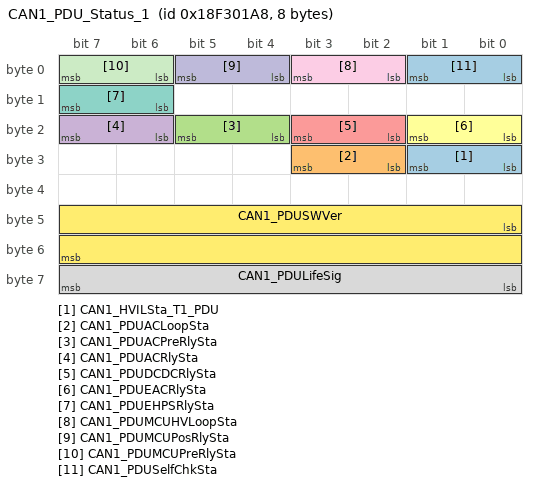
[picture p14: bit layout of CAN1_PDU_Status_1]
      frame CAN1_PDU_Status_1: id 0x18F301A8, frame-length=8, can-addressing-mode=EXTENDED, can-fd-frame-support=false, can-frame-rx-behavior=CAN-20, can-frame-tx-behavior=CAN-20
        pdu CAN1_PDU_Status_1: length=8, minimum-delay=0.0, transmission-mode-true-timing=cyclic-timing=time-period=0.1, unused-bit-pattern=0
          mapping CAN1_SG_PDU_Status_1: i-signal-group=CAN1_SG_PDU_Status_1, start-position=0, transfer-property=PENDING
          signal CAN1_HVILSta_T1_PDU: start 24, 2 bit, little-endian, i-signal-type=PRIMITIVE, init-value=constant-reference=Init_CAN1_HVILSta_T1_PDU, base-type=uint8, implementation-data-type=uint8, transfer-property=PENDING
          signal CAN1_PDUACLoopSta: start 26, 2 bit, little-endian, i-signal-type=PRIMITIVE, init-value=constant-reference=Init_CAN1_PDUACLoopSta, base-type=uint8, implementation-data-type=uint8, transfer-property=PENDING
          signal CAN1_PDUACPreRlySta: start 20, 2 bit, little-endian, i-signal-type=PRIMITIVE, init-value=constant-reference=Init_CAN1_PDUACPreRlySta, base-type=uint8, implementation-data-type=uint8, transfer-property=PENDING
          signal CAN1_PDUACRlySta: start 22, 2 bit, little-endian, i-signal-type=PRIMITIVE, init-value=constant-reference=Init_CAN1_PDUACRlySta, base-type=uint8, implementation-data-type=uint8, transfer-property=PENDING
          signal CAN1_PDUDCDCRlySta: start 18, 2 bit, little-endian, i-signal-type=PRIMITIVE, init-value=constant-reference=Init_CAN1_PDUDCDCRlySta, base-type=uint8, implementation-data-type=uint8, transfer-property=PENDING
          signal CAN1_PDUEACRlySta: start 16, 2 bit, little-endian, i-signal-type=PRIMITIVE, init-value=constant-reference=Init_CAN1_PDUEACRlySta, base-type=uint8, implementation-data-type=uint8, transfer-property=PENDING
          signal CAN1_PDUEHPSRlySta: start 14, 2 bit, little-endian, i-signal-type=PRIMITIVE, init-value=constant-reference=Init_CAN1_PDUEHPSRlySta, base-type=uint8, implementation-data-type=uint8, transfer-property=PENDING
          signal CAN1_PDULifeSig: start 56, 8 bit, little-endian, i-signal-type=PRIMITIVE, init-value=constant-reference=Init_CAN1_PDULifeSig, base-type=uint8, implementation-data-type=uint8, transfer-property=PENDING
          signal CAN1_PDUMCUHVLoopSta: start 2, 2 bit, little-endian, i-signal-type=PRIMITIVE, init-value=constant-reference=Init_CAN1_PDUMCUHVLoopSta, base-type=uint8, implementation-data-type=uint8, transfer-property=PENDING
          signal CAN1_PDUMCUPosRlySta: start 4, 2 bit, little-endian, i-signal-type=PRIMITIVE, init-value=constant-reference=Init_CAN1_PDUMCUPosRlySta, base-type=uint8, implementation-data-type=uint8, transfer-property=PENDING
          signal CAN1_PDUMCUPreRlySta: start 6, 2 bit, little-endian, i-signal-type=PRIMITIVE, init-value=constant-reference=Init_CAN1_PDUMCUPreRlySta, base-type=uint8, implementation-data-type=uint8, transfer-property=PENDING
          signal CAN1_PDUSWVer: start 40, 16 bit, little-endian, i-signal-type=PRIMITIVE, init-value=constant-reference=Init_CAN1_PDUSWVer, base-type=uint16, implementation-data-type=uint16, transfer-property=PENDING
          signal CAN1_PDUSelfChkSta: start 0, 2 bit, little-endian, i-signal-type=PRIMITIVE, init-value=constant-reference=Init_CAN1_PDUSelfChkSta, base-type=uint8, implementation-data-type=uint8, transfer-property=PENDING
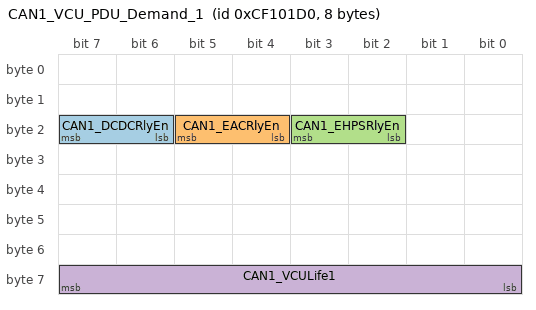
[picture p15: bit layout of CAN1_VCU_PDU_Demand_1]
      frame CAN1_VCU_PDU_Demand_1: id 0xCF101D0, frame-length=8, can-addressing-mode=EXTENDED, can-fd-frame-support=false, can-frame-rx-behavior=CAN-20, can-frame-tx-behavior=CAN-20
        pdu CAN1_VCU_PDU_Demand_1: length=8, minimum-delay=0.0, transmission-mode-true-timing=cyclic-timing=time-period=0.01, unused-bit-pattern=0
          mapping CAN1_SG_VCU_PDU_Demand_1: i-signal-group=CAN1_SG_VCU_PDU_Demand_1, start-position=0, transfer-property=PENDING
          signal CAN1_DCDCRlyEn: start 22, 2 bit, little-endian, i-signal-type=PRIMITIVE, init-value=constant-reference=Init_CAN1_DCDCRlyEn, base-type=uint8, implementation-data-type=uint8, transfer-property=PENDING
          signal CAN1_EACRlyEn: start 20, 2 bit, little-endian, i-signal-type=PRIMITIVE, init-value=constant-reference=Init_CAN1_EACRlyEn, base-type=uint8, implementation-data-type=uint8, transfer-property=PENDING
          signal CAN1_EHPSRlyEn: start 18, 2 bit, little-endian, i-signal-type=PRIMITIVE, init-value=constant-reference=Init_CAN1_EHPSRlyEn, base-type=uint8, implementation-data-type=uint8, transfer-property=PENDING
          signal CAN1_VCULife1: start 56, 8 bit, little-endian, i-signal-type=PRIMITIVE, init-value=constant-reference=Init_CAN1_VCULife1, base-type=uint8, implementation-data-type=uint8, transfer-property=PENDING
package /CAN1/ConstantSpecification
  176 x constant specification:
    Init_CAN1_AutoTracH: value-spec=0
    Init_CAN1_DamStiffReqFA: value-spec=0
    Init_CAN1_DamStiffReqLA: value-spec=0
    Init_CAN1_DamStiffReqRA: value-spec=0
    Init_CAN1_KneeCtrlMReq: value-spec=0
    Init_CAN1_KneeReqFA: value-spec=0
    Init_CAN1_KneeReqLSide: value-spec=0
    Init_CAN1_KneeReqRA: value-spec=0
    Init_CAN1_KneeReqRSide: value-spec=0
    Init_CAN1_LA1PosCmd: value-spec=0
    Init_CAN1_LA2PosCmd: value-spec=0
    Init_CAN1_LvCtrlModeReq: value-spec=0
    Init_CAN1_NLvReqFA: value-spec=0
    Init_CAN1_NLvReqRA: value-spec=0
    Init_CAN1_BrakeSW: value-spec=0
    Init_CAN1_ParkBrakeSW: value-spec=0
    Init_CAN1_VCUVehSpd: value-spec=0
    Init_CAN1_CFGEM1BAMPGN: value-spec=0
    Init_CAN1_CFGEM1BAMRsv: value-spec=0
    Init_CAN1_CFGEM1BAMTNum: value-spec=0
    Init_CAN1_CFGEM1BAMTSize: value-spec=0
    Init_CAN1_CFGEM1Ctrl: value-spec=0
    Init_CAN1_CFGEM1DT{0..7}: value-spec=0
    Init_CAN1_DCDCEnSta: value-spec=0
    Init_CAN1_DCDCErrCode: value-spec=0
    Init_CAN1_DCDCErrLv: value-spec=0
    Init_CAN1_DCDCInCurr: value-spec=0
    Init_CAN1_DCDCInVol: value-spec=0
    Init_CAN1_DCDCLifeSig: value-spec=0
    Init_CAN1_DCDCTempe: value-spec=0
    Init_CAN1_DCDCOutCurr: value-spec=0
    Init_CAN1_DCDCOutVol: value-spec=0
    Init_CAN1_DCDCSWVer: value-spec=0
    Init_CAN1_EACEnSta: value-spec=0
    Init_CAN1_EACErrCode: value-spec=0
    Init_CAN1_EACErrLv: value-spec=0
    Init_CAN1_EACHVILSig: value-spec=0
    Init_CAN1_EACInVol: value-spec=0
    Init_CAN1_EACInvTempe: value-spec=0
    Init_CAN1_EACLifeSig: value-spec=0
    Init_CAN1_EACMotorTempe: value-spec=0
    Init_CAN1_ABSFullyOper: value-spec=0
    Init_CAN1_ABSOffroadSw: value-spec=0
    Init_CAN1_ASRBrakeCtrlAtc: value-spec=0
    Init_CAN1_ASREngCtrlAtc: value-spec=0
    Init_CAN1_ASRHillHolderSw: value-spec=0
    Init_CAN1_ASROffroadSw: value-spec=0
    Init_CAN1_ATCASRInfoSig: value-spec=0
    Init_CAN1_AcltrInterlockSw: value-spec=0
    Init_CAN1_AntiLBrakABSAct: value-spec=0
    Init_CAN1_BrakePedalPos: value-spec=0
    Init_CAN1_EBSAmWarnLampSta: value-spec=0
    Init_CAN1_EBSBrakeSw: value-spec=0
    Init_CAN1_EBSRedWarnLampSta: value-spec=0
    Init_CAN1_EngAuxShutdownSw: value-spec=0
    Init_CAN1_EngDerateSw: value-spec=0
    Init_CAN1_EngRetSel: value-spec=0
    Init_CAN1_HaltBrakeSw: value-spec=0
    Init_CAN1_RmAccelEnSw: value-spec=0
    Init_CAN1_SACtrlBrakeCtrl: value-spec=0
    Init_CAN1_TractCtrlOvrSw: value-spec=0
    Init_CAN1_TrailerABSSta: value-spec=0
    Init_CAN1_TrailerABSWarnSig: value-spec=0
    Init_CAN1_FASpeed: value-spec=0
    Init_CAN1_RelaSpdFALWheel: value-spec=0
    Init_CAN1_RelaSpdFARWheel: value-spec=0
    Init_CAN1_RelaSpdRA1LWheel: value-spec=0
    Init_CAN1_RelaSpdRA1RWheel: value-spec=0
    Init_CAN1_RelaSpdRA2LWheel: value-spec=0
    Init_CAN1_RelaSpdRA2RWheel: value-spec=0
    Init_CAN1_BrkTempeWarn: value-spec=0
    Init_CAN1_FndBrkUse: value-spec=0
    Init_CAN1_HaltBrkMode: value-spec=0
    Init_CAN1_HillHolderMode: value-spec=0
    Init_CAN1_ParkBrkActuFAct: value-spec=0
    Init_CAN1_XBRAcltnLimit: value-spec=0
    Init_CAN1_XBRActtrlMode: value-spec=0
    Init_CAN1_XBRSysSta: value-spec=0
    Init_CAN1_AccPedal1LowSW: value-spec=0
    Init_CAN1_AccPedalPos1: value-spec=0
    Init_CAN1_EEC2MSGCS: value-spec=0
    Init_CAN1_EEC2MSGCnt: value-spec=0
    Init_CAN1_EMParasLoss: value-spec=125
    Init_CAN1_NFricPercTorq: value-spec=125
    Init_CAN1_EHPSEnSta: value-spec=0
    Init_CAN1_EHPSErrCode: value-spec=0
    Init_CAN1_EHPSErrLv: value-spec=0
    Init_CAN1_EHPSHVILSig: value-spec=0
    Init_CAN1_EHPSInVol: value-spec=0
    Init_CAN1_EHPSInvTemp: value-spec=0
    Init_CAN1_EHPSLifeSig: value-spec=0
    Init_CAN1_EHPSMotorTempe: value-spec=0
    Init_CAN1_EM1CS: value-spec=0
    Init_CAN1_EM1Cnt: value-spec=0
    Init_CAN1_EM1OvrCtrlMBrk: value-spec=0
    Init_CAN1_EM1OvrCtrlMDriv: value-spec=0
    Init_CAN1_EM1OvrCtrlMPriBrk: value-spec=0
    Init_CAN1_EM1OvrCtrlMPriDriv: value-spec=0
    Init_CAN1_EM1ReqTorqHRlsBrk: value-spec=15
    Init_CAN1_EM1ReqTorqHRlsDri: value-spec=15
    Init_CAN1_EM1ReqTorqLimBrk: value-spec=0
    Init_CAN1_EM1ReqTorqLimDriv: value-spec=0
    Init_CAN1_ActEMOutSftSpd: value-spec=0
    Init_CAN1_ActEMpTrq: value-spec=125
    Init_CAN1_ActEMpTrqHrls: value-spec=0
    Init_CAN1_ActMaxAvaEMRecpTrq: value-spec=125
    Init_CAN1_DrvDemEMRtapTrq: value-spec=125
    Init_CAN1_EMTrqModeDrvBrk: value-spec=0
    Init_CAN1_RetSelNonEng: value-spec=125
    Init_CAN1_SACtrlDev: value-spec=0
    Init_CAN1_EPB_ParkingBrake_Sta: value-spec=0
    Init_CAN1_DLEngaged: value-spec=0
    Init_CAN1_ShiftPgs: value-spec=0
    Init_CAN1_ActDriveDirect: value-spec=125
    Init_CAN1_FDC_CHA_EBSHBSw_Sta: value-spec=0
    Init_CAN1_FDC_CHA_EBSHHSw_Sta: value-spec=0
    Init_CAN1_FDC_CHA_EBSRd4BR_Sta: value-spec=0
    Init_CAN1_DCDCEnDemand: value-spec=0
    Init_CAN1_EACSpdDemand: value-spec=10000
    Init_CAN1_EHPSEnDemand: value-spec=0
    Init_CAN1_EHPSSpdDemand: value-spec=10000
    Init_CAN1_FDC_CHA_EACEnDemand_Cmd: value-spec=0
    Init_CAN1_FDC_BCM_DoorSta_Sta: value-spec=0
    Init_CAN1_SeatBeltSwitch: value-spec=0
    Init_CAN1_OpenStatusOfDoor1: value-spec=0
    Init_CAN1_OpenStatusOfDoor2: value-spec=0
    Init_CAN1_HVILSta_T1_PDU: value-spec=0
    Init_CAN1_PDUACLoopSta: value-spec=0
    Init_CAN1_PDUACPreRlySta: value-spec=0
    Init_CAN1_PDUACRlySta: value-spec=0
    Init_CAN1_PDUDCDCRlySta: value-spec=0
    Init_CAN1_PDUEACRlySta: value-spec=0
    Init_CAN1_PDUEHPSRlySta: value-spec=0
    Init_CAN1_PDULifeSig: value-spec=0
    Init_CAN1_PDUMCUHVLoopSta: value-spec=0
    Init_CAN1_PDUMCUPosRlySta: value-spec=0
    Init_CAN1_PDUMCUPreRlySta: value-spec=0
    Init_CAN1_PDUSWVer: value-spec=0
    Init_CAN1_PDUSelfChkSta: value-spec=0
    Init_CAN1_DCDCRlyEn: value-spec=0
    Init_CAN1_EACRlyEn: value-spec=0
    Init_CAN1_EHPSRlyEn: value-spec=0
    Init_CAN1_VCULife1: value-spec=0
    Init_CAN1_SG_ASC2_A: value-spec=fields=[Init_CAN1_AutoTracH, Init_CAN1_DamStiffReqFA, Init_CAN1_DamStiffReqLA, Init_CAN1_DamStiffReqRA, Init_CAN1_KneeCtrlMReq, Init_CAN1_KneeReqFA, Init_CAN1_KneeReqLSide, Init_CAN1_KneeReqRA, Init_CAN1_KneeReqRSide, Init_CAN1_LA1PosCmd, Init_CAN1_LA2PosCmd, Init_CAN1_LvCtrlModeReq, Init_CAN1_NLvReqFA, Init_CAN1_NLvReqRA]
    Init_CAN1_SG_CCVS: value-spec=fields=[Init_CAN1_BrakeSW, Init_CAN1_ParkBrakeSW, Init_CAN1_VCUVehSpd]
    Init_CAN1_SG_CFGEM1_BAM: value-spec=fields=[Init_CAN1_CFGEM1BAMPGN, Init_CAN1_CFGEM1BAMRsv, Init_CAN1_CFGEM1BAMTNum, Init_CAN1_CFGEM1BAMTSize, Init_CAN1_CFGEM1Ctrl]
    Init_CAN1_SG_CFGEM1_DT: value-spec=fields=[Init_CAN1_CFGEM1DT0, Init_CAN1_CFGEM1DT1, Init_CAN1_CFGEM1DT2, Init_CAN1_CFGEM1DT3, Init_CAN1_CFGEM1DT4, Init_CAN1_CFGEM1DT5, Init_CAN1_CFGEM1DT6, Init_CAN1_CFGEM1DT7]
    Init_CAN1_SG_DCDC_Status_1: value-spec=fields=[Init_CAN1_DCDCEnSta, Init_CAN1_DCDCErrCode, Init_CAN1_DCDCErrLv, Init_CAN1_DCDCInCurr, Init_CAN1_DCDCInVol, Init_CAN1_DCDCLifeSig, Init_CAN1_DCDCTempe]
    Init_CAN1_SG_DCDC_Status_2: value-spec=fields=[Init_CAN1_DCDCOutCurr, Init_CAN1_DCDCOutVol, Init_CAN1_DCDCSWVer]
    Init_CAN1_SG_EAC_Status_1: value-spec=fields=[Init_CAN1_EACEnSta, Init_CAN1_EACErrCode, Init_CAN1_EACErrLv, Init_CAN1_EACHVILSig, Init_CAN1_EACInVol, Init_CAN1_EACInvTempe, Init_CAN1_EACLifeSig, Init_CAN1_EACMotorTempe]
    Init_CAN1_SG_EBC1: value-spec=fields=[Init_CAN1_ABSFullyOper, Init_CAN1_ABSOffroadSw, Init_CAN1_ASRBrakeCtrlAtc, Init_CAN1_ASREngCtrlAtc, Init_CAN1_ASRHillHolderSw, Init_CAN1_ASROffroadSw, Init_CAN1_ATCASRInfoSig, Init_CAN1_AcltrInterlockSw, Init_CAN1_AntiLBrakABSAct, Init_CAN1_BrakePedalPos, Init_CAN1_EBSAmWarnLampSta, Init_CAN1_EBSBrakeSw, Init_CAN1_EBSRedWarnLampSta, Init_CAN1_EngAuxShutdownSw, Init_CAN1_EngDerateSw, Init_CAN1_EngRetSel, Init_CAN1_HaltBrakeSw, Init_CAN1_RmAccelEnSw, Init_CAN1_SACtrlBrakeCtrl, Init_CAN1_TractCtrlOvrSw, Init_CAN1_TrailerABSSta, Init_CAN1_TrailerABSWarnSig]
    Init_CAN1_SG_EBC2: value-spec=fields=[Init_CAN1_FASpeed, Init_CAN1_RelaSpdFALWheel, Init_CAN1_RelaSpdFARWheel, Init_CAN1_RelaSpdRA1LWheel, Init_CAN1_RelaSpdRA1RWheel, Init_CAN1_RelaSpdRA2LWheel, Init_CAN1_RelaSpdRA2RWheel]
    Init_CAN1_SG_EBC5: value-spec=fields=[Init_CAN1_BrkTempeWarn, Init_CAN1_FndBrkUse, Init_CAN1_HaltBrkMode, Init_CAN1_HillHolderMode, Init_CAN1_ParkBrkActuFAct, Init_CAN1_XBRAcltnLimit, Init_CAN1_XBRActtrlMode, Init_CAN1_XBRSysSta]
    Init_CAN1_SG_EEC2: value-spec=fields=[Init_CAN1_AccPedal1LowSW, Init_CAN1_AccPedalPos1, Init_CAN1_EEC2MSGCS, Init_CAN1_EEC2MSGCnt]
    Init_CAN1_SG_EEC3: value-spec=fields=[Init_CAN1_EMParasLoss, Init_CAN1_NFricPercTorq]
    Init_CAN1_SG_EHPS_Status_1: value-spec=fields=[Init_CAN1_EHPSEnSta, Init_CAN1_EHPSErrCode, Init_CAN1_EHPSErrLv, Init_CAN1_EHPSHVILSig, Init_CAN1_EHPSInVol, Init_CAN1_EHPSInvTemp, Init_CAN1_EHPSLifeSig, Init_CAN1_EHPSMotorTempe]
    Init_CAN1_SG_EMC1_EM1: value-spec=fields=[Init_CAN1_EM1CS, Init_CAN1_EM1Cnt, Init_CAN1_EM1OvrCtrlMBrk, Init_CAN1_EM1OvrCtrlMDriv, Init_CAN1_EM1OvrCtrlMPriBrk, Init_CAN1_EM1OvrCtrlMPriDriv, Init_CAN1_EM1ReqTorqHRlsBrk, Init_CAN1_EM1ReqTorqHRlsDri, Init_CAN1_EM1ReqTorqLimBrk, Init_CAN1_EM1ReqTorqLimDriv]
    Init_CAN1_SG_EMRC1: value-spec=fields=[Init_CAN1_ActEMOutSftSpd, Init_CAN1_ActEMpTrq, Init_CAN1_ActEMpTrqHrls, Init_CAN1_ActMaxAvaEMRecpTrq, Init_CAN1_DrvDemEMRtapTrq, Init_CAN1_EMTrqModeDrvBrk, Init_CAN1_RetSelNonEng, Init_CAN1_SACtrlDev]
    Init_CAN1_SG_EPB1: value-spec=fields=constant-reference=Init_CAN1_EPB_ParkingBrake_Sta
    Init_CAN1_SG_ETC1: value-spec=fields=[Init_CAN1_DLEngaged, Init_CAN1_ShiftPgs]
    Init_CAN1_SG_ETC2: value-spec=fields=constant-reference=Init_CAN1_ActDriveDirect
    Init_CAN1_SG_FD1_C100_1: value-spec=fields=[Init_CAN1_FDC_CHA_EBSHBSw_Sta, Init_CAN1_FDC_CHA_EBSHHSw_Sta]
    Init_CAN1_SG_FD1_C100_2: value-spec=fields=constant-reference=Init_CAN1_FDC_CHA_EBSRd4BR_Sta
    Init_CAN1_SG_FD1_C100_3: value-spec=fields=[Init_CAN1_DCDCEnDemand, Init_CAN1_EACSpdDemand, Init_CAN1_EHPSEnDemand, Init_CAN1_EHPSSpdDemand, Init_CAN1_FDC_CHA_EACEnDemand_Cmd]
    Init_CAN1_SG_FD1_CE100_1: value-spec=fields=constant-reference=Init_CAN1_FDC_BCM_DoorSta_Sta
    Init_CAN1_SG_GW1_C1000_1: value-spec=fields=constant-reference=Init_CAN1_SeatBeltSwitch
    Init_CAN1_SG_GW1_C100_4: value-spec=fields=[Init_CAN1_OpenStatusOfDoor1, Init_CAN1_OpenStatusOfDoor2]
    Init_CAN1_SG_PDU_Status_1: value-spec=fields=[Init_CAN1_HVILSta_T1_PDU, Init_CAN1_PDUACLoopSta, Init_CAN1_PDUACPreRlySta, Init_CAN1_PDUACRlySta, Init_CAN1_PDUDCDCRlySta, Init_CAN1_PDUEACRlySta, Init_CAN1_PDUEHPSRlySta, Init_CAN1_PDULifeSig, Init_CAN1_PDUMCUHVLoopSta, Init_CAN1_PDUMCUPosRlySta, Init_CAN1_PDUMCUPreRlySta, Init_CAN1_PDUSWVer, Init_CAN1_PDUSelfChkSta]
    Init_CAN1_SG_VCU_PDU_Demand_1: value-spec=fields=[Init_CAN1_DCDCRlyEn, Init_CAN1_EACRlyEn, Init_CAN1_EHPSRlyEn, Init_CAN1_VCULife1]
package /CAN1/ImplementationDataTypes
  26 x impl type, all with category=STRUCTURE:
    DT_CAN1_SG_ASC2_A
      14 x element, all with category=TYPE_REFERENCE, implementation-data-type=uint8:
        CAN1_AutoTracH
        CAN1_DamStiffReqFA
        CAN1_DamStiffReqLA
        CAN1_DamStiffReqRA
        CAN1_KneeCtrlMReq
        CAN1_KneeReqFA
        CAN1_KneeReqLSide
        CAN1_KneeReqRA
        CAN1_KneeReqRSide
        CAN1_LA1PosCmd
        CAN1_LA2PosCmd
        CAN1_LvCtrlModeReq
        CAN1_NLvReqFA
        CAN1_NLvReqRA
    DT_CAN1_SG_CCVS
      element CAN1_BrakeSW: implementation-data-type=uint8
      element CAN1_ParkBrakeSW: implementation-data-type=uint8
      element CAN1_VCUVehSpd: implementation-data-type=uint16
    DT_CAN1_SG_CFGEM1_BAM
      5 x element, all with category=TYPE_REFERENCE:
        CAN1_CFGEM1BAMPGN: implementation-data-type=uint32
        CAN1_CFGEM1BAMRsv: implementation-data-type=uint8
        CAN1_CFGEM1BAMTNum: implementation-data-type=uint8
        CAN1_CFGEM1BAMTSize: implementation-data-type=uint16
        CAN1_CFGEM1Ctrl: implementation-data-type=uint8
    DT_CAN1_SG_CFGEM1_DT
      8 x element, all with category=TYPE_REFERENCE, implementation-data-type=uint8:
        CAN1_CFGEM1DT{0..7}
    DT_CAN1_SG_DCDC_Status_1
      7 x element, all with category=TYPE_REFERENCE:
        CAN1_DCDCEnSta: implementation-data-type=uint8
        CAN1_DCDCErrCode: implementation-data-type=uint8
        CAN1_DCDCErrLv: implementation-data-type=uint8
        CAN1_DCDCInCurr: implementation-data-type=uint16
        CAN1_DCDCInVol: implementation-data-type=uint16
        CAN1_DCDCLifeSig: implementation-data-type=uint8
        CAN1_DCDCTempe: implementation-data-type=uint8
    DT_CAN1_SG_DCDC_Status_2
      element CAN1_DCDCOutCurr: implementation-data-type=uint16
      element CAN1_DCDCOutVol: implementation-data-type=uint16
      element CAN1_DCDCSWVer: implementation-data-type=uint16
    DT_CAN1_SG_EAC_Status_1
      8 x element, all with category=TYPE_REFERENCE:
        CAN1_EACEnSta: implementation-data-type=uint8
        CAN1_EACErrCode: implementation-data-type=uint8
        CAN1_EACErrLv: implementation-data-type=uint8
        CAN1_EACHVILSig: implementation-data-type=uint8
        CAN1_EACInVol: implementation-data-type=uint16
        CAN1_EACInvTempe: implementation-data-type=uint8
        CAN1_EACLifeSig: implementation-data-type=uint8
        CAN1_EACMotorTempe: implementation-data-type=uint8
    DT_CAN1_SG_EBC1
      22 x element, all with category=TYPE_REFERENCE, implementation-data-type=uint8:
        CAN1_ABSFullyOper
        CAN1_ABSOffroadSw
        CAN1_ASRBrakeCtrlAtc
        CAN1_ASREngCtrlAtc
        CAN1_ASRHillHolderSw
        CAN1_ASROffroadSw
        CAN1_ATCASRInfoSig
        CAN1_AcltrInterlockSw
        CAN1_AntiLBrakABSAct
        CAN1_BrakePedalPos
        CAN1_EBSAmWarnLampSta
        CAN1_EBSBrakeSw
        CAN1_EBSRedWarnLampSta
        CAN1_EngAuxShutdownSw
        CAN1_EngDerateSw
        CAN1_EngRetSel
        CAN1_HaltBrakeSw
        CAN1_RmAccelEnSw
        CAN1_SACtrlBrakeCtrl
        CAN1_TractCtrlOvrSw
        CAN1_TrailerABSSta
        CAN1_TrailerABSWarnSig
    DT_CAN1_SG_EBC2
      7 x element, all with category=TYPE_REFERENCE:
        CAN1_FASpeed: implementation-data-type=uint16
        CAN1_RelaSpdFALWheel: implementation-data-type=uint8
        CAN1_RelaSpdFARWheel: implementation-data-type=uint8
        CAN1_RelaSpdRA1LWheel: implementation-data-type=uint8
        CAN1_RelaSpdRA1RWheel: implementation-data-type=uint8
        CAN1_RelaSpdRA2LWheel: implementation-data-type=uint8
        CAN1_RelaSpdRA2RWheel: implementation-data-type=uint8
    DT_CAN1_SG_EBC5
      8 x element, all with category=TYPE_REFERENCE, implementation-data-type=uint8:
        CAN1_BrkTempeWarn
        CAN1_FndBrkUse
        CAN1_HaltBrkMode
        CAN1_HillHolderMode
        CAN1_ParkBrkActuFAct
        CAN1_XBRAcltnLimit
        CAN1_XBRActtrlMode
        CAN1_XBRSysSta
    DT_CAN1_SG_EEC2
      4 x element, all with category=TYPE_REFERENCE, implementation-data-type=uint8:
        CAN1_AccPedal1LowSW
        CAN1_AccPedalPos1
        CAN1_EEC2MSGCS
        CAN1_EEC2MSGCnt
    DT_CAN1_SG_EEC3
      element CAN1_EMParasLoss: implementation-data-type=uint8
      element CAN1_NFricPercTorq: implementation-data-type=uint8
    DT_CAN1_SG_EHPS_Status_1
      8 x element, all with category=TYPE_REFERENCE:
        CAN1_EHPSEnSta: implementation-data-type=uint8
        CAN1_EHPSErrCode: implementation-data-type=uint8
        CAN1_EHPSErrLv: implementation-data-type=uint8
        CAN1_EHPSHVILSig: implementation-data-type=uint8
        CAN1_EHPSInVol: implementation-data-type=uint16
        CAN1_EHPSInvTemp: implementation-data-type=uint8
        CAN1_EHPSLifeSig: implementation-data-type=uint8
        CAN1_EHPSMotorTempe: implementation-data-type=uint8
    DT_CAN1_SG_EMC1_EM1
      10 x element, all with category=TYPE_REFERENCE, implementation-data-type=uint8:
        CAN1_EM1CS
        CAN1_EM1Cnt
        CAN1_EM1OvrCtrlMBrk
        CAN1_EM1OvrCtrlMDriv
        CAN1_EM1OvrCtrlMPriBrk
        CAN1_EM1OvrCtrlMPriDriv
        CAN1_EM1ReqTorqHRlsBrk
        CAN1_EM1ReqTorqHRlsDri
        CAN1_EM1ReqTorqLimBrk
        CAN1_EM1ReqTorqLimDriv
    DT_CAN1_SG_EMRC1
      8 x element, all with category=TYPE_REFERENCE:
        CAN1_ActEMOutSftSpd: implementation-data-type=uint16
        CAN1_ActEMpTrq: implementation-data-type=uint8
        CAN1_ActEMpTrqHrls: implementation-data-type=uint8
        CAN1_ActMaxAvaEMRecpTrq: implementation-data-type=uint8
        CAN1_DrvDemEMRtapTrq: implementation-data-type=uint8
        CAN1_EMTrqModeDrvBrk: implementation-data-type=uint8
        CAN1_RetSelNonEng: implementation-data-type=uint8
        CAN1_SACtrlDev: implementation-data-type=uint8
    DT_CAN1_SG_EPB1
      element CAN1_EPB_ParkingBrake_Sta: implementation-data-type=uint8
    DT_CAN1_SG_ETC1
      element CAN1_DLEngaged: implementation-data-type=uint8
      element CAN1_ShiftPgs: implementation-data-type=uint8
    DT_CAN1_SG_ETC2
      element CAN1_ActDriveDirect: implementation-data-type=uint8
    DT_CAN1_SG_FD1_C100_1
      element CAN1_FDC_CHA_EBSHBSw_Sta: implementation-data-type=uint8
      element CAN1_FDC_CHA_EBSHHSw_Sta: implementation-data-type=uint8
    DT_CAN1_SG_FD1_C100_2
      element CAN1_FDC_CHA_EBSRd4BR_Sta: implementation-data-type=uint8
    DT_CAN1_SG_FD1_C100_3
      5 x element, all with category=TYPE_REFERENCE:
        CAN1_DCDCEnDemand: implementation-data-type=uint8
        CAN1_EACSpdDemand: implementation-data-type=uint16
        CAN1_EHPSEnDemand: implementation-data-type=uint8
        CAN1_EHPSSpdDemand: implementation-data-type=uint16
        CAN1_FDC_CHA_EACEnDemand_Cmd: implementation-data-type=uint8
    DT_CAN1_SG_FD1_CE100_1
      element CAN1_FDC_BCM_DoorSta_Sta: implementation-data-type=uint8
    DT_CAN1_SG_GW1_C1000_1
      element CAN1_SeatBeltSwitch: implementation-data-type=uint8
    DT_CAN1_SG_GW1_C100_4
      element CAN1_OpenStatusOfDoor1: implementation-data-type=uint8
      element CAN1_OpenStatusOfDoor2: implementation-data-type=uint8
    DT_CAN1_SG_PDU_Status_1
      13 x element, all with category=TYPE_REFERENCE:
        CAN1_HVILSta_T1_PDU: implementation-data-type=uint8
        CAN1_PDUACLoopSta: implementation-data-type=uint8
        CAN1_PDUACPreRlySta: implementation-data-type=uint8
        CAN1_PDUACRlySta: implementation-data-type=uint8
        CAN1_PDUDCDCRlySta: implementation-data-type=uint8
        CAN1_PDUEACRlySta: implementation-data-type=uint8
        CAN1_PDUEHPSRlySta: implementation-data-type=uint8
        CAN1_PDULifeSig: implementation-data-type=uint8
        CAN1_PDUMCUHVLoopSta: implementation-data-type=uint8
        CAN1_PDUMCUPosRlySta: implementation-data-type=uint8
        CAN1_PDUMCUPreRlySta: implementation-data-type=uint8
        CAN1_PDUSWVer: implementation-data-type=uint16
        CAN1_PDUSelfChkSta: implementation-data-type=uint8
    DT_CAN1_SG_VCU_PDU_Demand_1
      4 x element, all with category=TYPE_REFERENCE, implementation-data-type=uint8:
        CAN1_DCDCRlyEn
        CAN1_EACRlyEn
        CAN1_EHPSRlyEn
        CAN1_VCULife1
